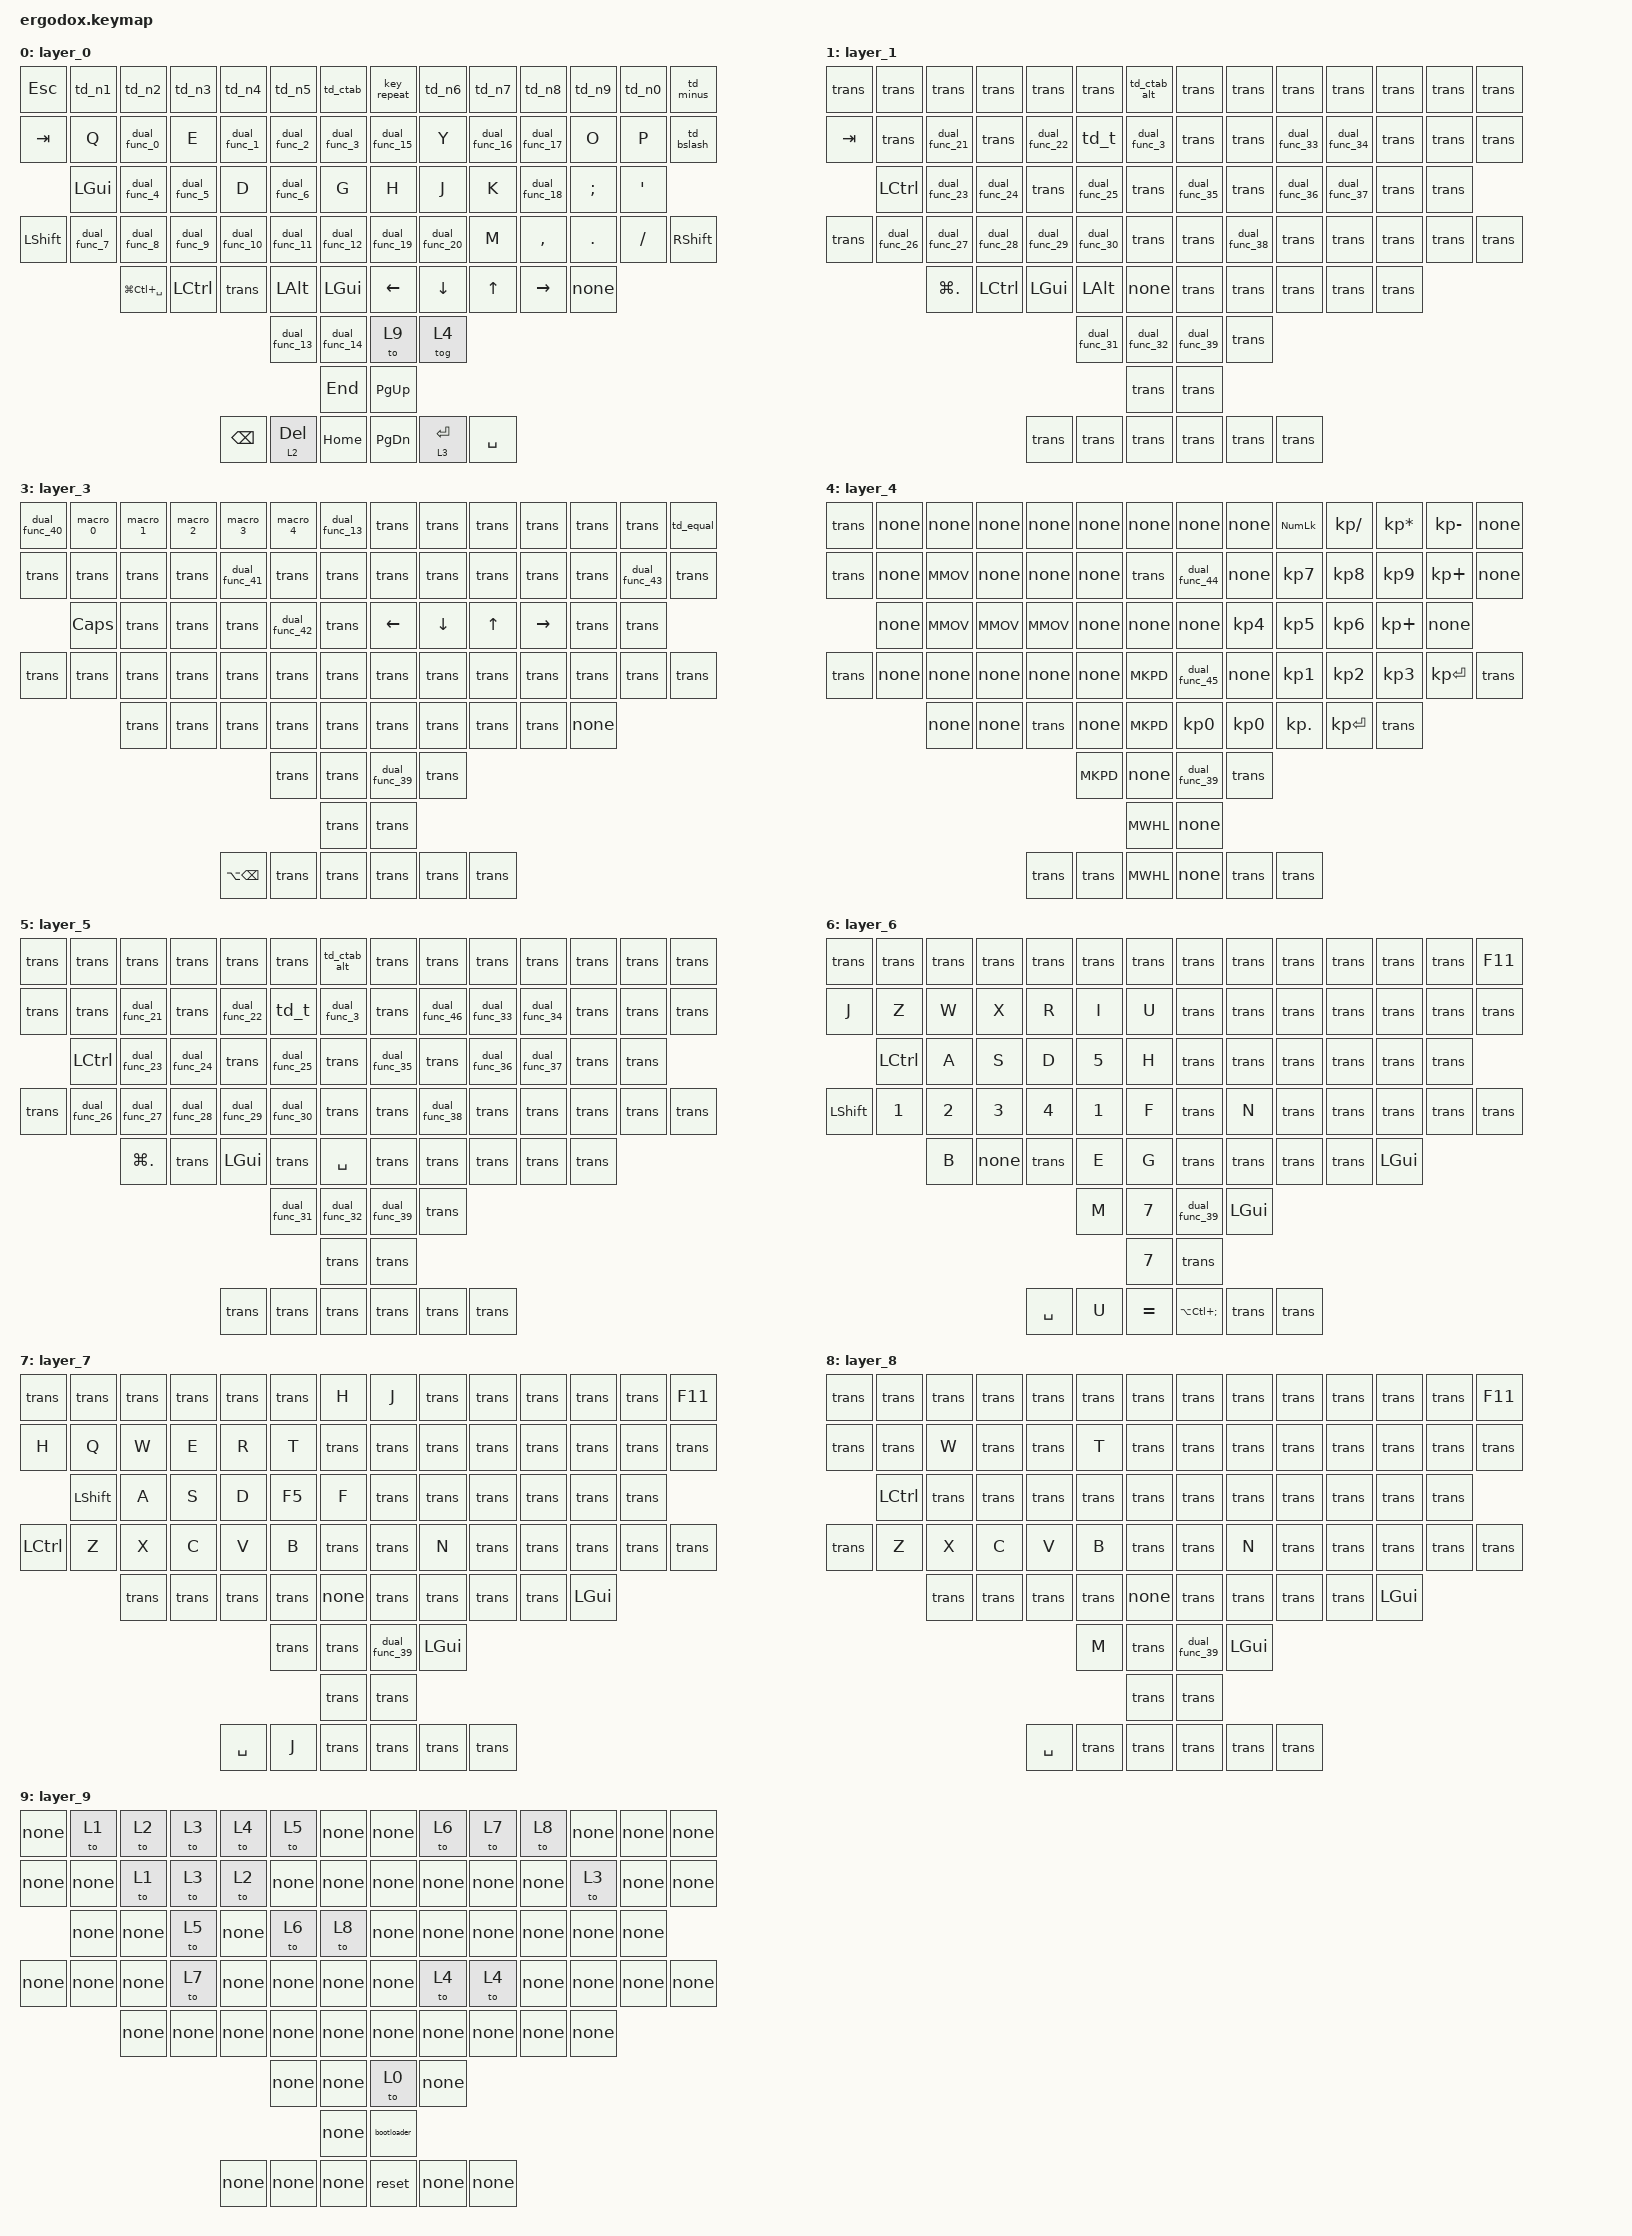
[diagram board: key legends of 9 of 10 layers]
// Auto-generated by qmk_to_zmk.py - Complete keymap conversion
#include <dt-bindings/zmk/keys.h>

/ {
    behaviors {
        // Tri-function number row (tap=number, hold=symbol via mod-tap first binding, double-tap=Fx second binding)
        td_n1: td_n1 { compatible = "zmk,behavior-tap-dance"; #binding-cells = <0>; tapping-term-ms = <300>; bindings = <&mt EXCL N1>, <&kp F1>; };
        td_n2: td_n2 { compatible = "zmk,behavior-tap-dance"; #binding-cells = <0>; tapping-term-ms = <300>; bindings = <&mt AT N2>, <&kp F2>; };
        td_n3: td_n3 { compatible = "zmk,behavior-tap-dance"; #binding-cells = <0>; tapping-term-ms = <300>; bindings = <&mt HASH N3>, <&kp F3>; };
        td_n4: td_n4 { compatible = "zmk,behavior-tap-dance"; #binding-cells = <0>; tapping-term-ms = <300>; bindings = <&mt DLLR N4>, <&kp F4>; };
        td_n5: td_n5 { compatible = "zmk,behavior-tap-dance"; #binding-cells = <0>; tapping-term-ms = <300>; bindings = <&mt PRCNT N5>, <&kp F5>; };
        td_ctab: td_ctab { compatible = "zmk,behavior-tap-dance"; #binding-cells = <0>; tapping-term-ms = <300>; bindings = <&mt LG(LS(A)) LC(TAB)>, <&kp LG(LEFT)>; };
        td_n6: td_n6 { compatible = "zmk,behavior-tap-dance"; #binding-cells = <0>; tapping-term-ms = <300>; bindings = <&mt CARET N6>, <&kp F6>; };
        td_n7: td_n7 { compatible = "zmk,behavior-tap-dance"; #binding-cells = <0>; tapping-term-ms = <300>; bindings = <&mt AMPS N7>, <&kp F7>; };
        td_n8: td_n8 { compatible = "zmk,behavior-tap-dance"; #binding-cells = <0>; tapping-term-ms = <300>; bindings = <&mt ASTRK N8>, <&kp F8>; };
        td_n9: td_n9 { compatible = "zmk,behavior-tap-dance"; #binding-cells = <0>; tapping-term-ms = <300>; bindings = <&mt LPAR N9>, <&kp F9>; };
        td_n0: td_n0 { compatible = "zmk,behavior-tap-dance"; #binding-cells = <0>; tapping-term-ms = <300>; bindings = <&mt RPAR N0>, <&kp F10>; };
        td_minus: td_minus { compatible = "zmk,behavior-tap-dance"; #binding-cells = <0>; tapping-term-ms = <250>; bindings = <&mt UNDER MINUS>, <&kp F11>; };
        td_bslash: td_bslash { compatible = "zmk,behavior-tap-dance"; #binding-cells = <0>; tapping-term-ms = <250>; bindings = <&kp BSLH>, <&kp F12>; };
        td_equal: td_equal { compatible = "zmk,behavior-tap-dance"; #binding-cells = <0>; tapping-term-ms = <250>; bindings = <&mt PLUS EQUAL>, <&kp F12>; };

        // Reused tap dances (workspace, T chord, desktop nav variants)
        td_ctab_alt: td_ctab_alt { compatible = "zmk,behavior-tap-dance"; #binding-cells = <0>; tapping-term-ms = <300>; bindings = <&mt LC(LS(A)) LC(TAB)>, <&kp LA(LEFT)>; };
        td_t: td_t { compatible = "zmk,behavior-tap-dance"; #binding-cells = <0>; tapping-term-ms = <300>; bindings = <&mt LC(T) T>, <&kp LC(LS(T))>; };
        td_t_alt: td_t_alt { compatible = "zmk,behavior-tap-dance"; #binding-cells = <0>; tapping-term-ms = <300>; bindings = <&mt LC(T) T>, <&kp LC(LS(T))>; };
        td_desktop_left: td_desktop_left { compatible = "zmk,behavior-tap-dance"; #binding-cells = <0>; tapping-term-ms = <300>; bindings = <&kp LA(LC(LG(LS(LEFT))))>, <&kp LA(LC(LG(LEFT)))>; };
        td_desktop_right: td_desktop_right { compatible = "zmk,behavior-tap-dance"; #binding-cells = <0>; tapping-term-ms = <300>; bindings = <&kp LA(LC(LG(LS(RIGHT))))>, <&kp LA(LC(LG(RIGHT)))>; };
        td_desktop_left_alt: td_desktop_left_alt { compatible = "zmk,behavior-tap-dance"; #binding-cells = <0>; tapping-term-ms = <300>; bindings = <&kp LA(LC(LG(LS(LEFT))))>, <&kp LA(LC(LG(LEFT)))>; };
        td_desktop_right_alt: td_desktop_right_alt { compatible = "zmk,behavior-tap-dance"; #binding-cells = <0>; tapping-term-ms = <300>; bindings = <&kp LA(LC(LG(LS(RIGHT))))>, <&kp LA(LC(LG(RIGHT)))>; };

        // Dual-function hold-tap keys
        dual_func_0: dual_func_0 { compatible = "zmk,behavior-hold-tap"; #binding-cells = <2>; flavor = "tap-preferred"; tapping-term-ms = <350>; bindings = <&kp LG(W)>, <&kp W>; };
        dual_func_1: dual_func_1 { compatible = "zmk,behavior-hold-tap"; #binding-cells = <2>; flavor = "tap-preferred"; tapping-term-ms = <300>; bindings = <&kp LG(R)>, <&kp R>; };
        dual_func_2: dual_func_2 { compatible = "zmk,behavior-hold-tap"; #binding-cells = <2>; flavor = "tap-preferred"; tapping-term-ms = <350>; bindings = <&kp LG(T)>, <&kp T>; };
        dual_func_3: dual_func_3 { compatible = "zmk,behavior-hold-tap"; #binding-cells = <2>; flavor = "tap-preferred"; tapping-term-ms = <300>; bindings = <&kp TILDE>, <&kp GRAVE>; };
        dual_func_4: dual_func_4 { compatible = "zmk,behavior-hold-tap"; #binding-cells = <2>; flavor = "tap-preferred"; tapping-term-ms = <300>; bindings = <&kp LG(A)>, <&kp A>; };
        dual_func_5: dual_func_5 { compatible = "zmk,behavior-hold-tap"; #binding-cells = <2>; flavor = "tap-preferred"; tapping-term-ms = <300>; bindings = <&kp LG(S)>, <&kp S>; };
        dual_func_6: dual_func_6 { compatible = "zmk,behavior-hold-tap"; #binding-cells = <2>; flavor = "tap-preferred"; tapping-term-ms = <300>; bindings = <&kp LG(F)>, <&kp F>; };
        dual_func_7: dual_func_7 { compatible = "zmk,behavior-hold-tap"; #binding-cells = <2>; flavor = "tap-preferred"; tapping-term-ms = <300>; bindings = <&kp LG(Z)>, <&kp Z>; };
        dual_func_8: dual_func_8 { compatible = "zmk,behavior-hold-tap"; #binding-cells = <2>; flavor = "tap-preferred"; tapping-term-ms = <300>; bindings = <&kp LG(X)>, <&kp X>; };
        dual_func_9: dual_func_9 { compatible = "zmk,behavior-hold-tap"; #binding-cells = <2>; flavor = "tap-preferred"; tapping-term-ms = <300>; bindings = <&kp LG(C)>, <&kp C>; };
        dual_func_10: dual_func_10 { compatible = "zmk,behavior-hold-tap"; #binding-cells = <2>; flavor = "tap-preferred"; tapping-term-ms = <300>; bindings = <&kp LG(V)>, <&kp V>; };
        dual_func_11: dual_func_11 { compatible = "zmk,behavior-hold-tap"; #binding-cells = <2>; flavor = "tap-preferred"; tapping-term-ms = <300>; bindings = <&kp LG(B)>, <&kp B>; };
        dual_func_12: dual_func_12 { compatible = "zmk,behavior-hold-tap"; #binding-cells = <2>; flavor = "tap-preferred"; tapping-term-ms = <300>; bindings = <&kp LPAR>, <&kp LBKT>; };
        dual_func_13: dual_func_13 { compatible = "zmk,behavior-hold-tap"; #binding-cells = <2>; flavor = "tap-preferred"; tapping-term-ms = <300>; bindings = <&kp LG(LS(N2))>, <&kp LG(LS(N1))>; };
        dual_func_14: dual_func_14 { compatible = "zmk,behavior-hold-tap"; #binding-cells = <2>; flavor = "tap-preferred"; tapping-term-ms = <300>; bindings = <&kp LG(LC(Q))>, <&kp C_PLAY_PAUSE>; };
        dual_func_15: dual_func_15 { compatible = "zmk,behavior-hold-tap"; #binding-cells = <2>; flavor = "tap-preferred"; tapping-term-ms = <200>; bindings = <&kp PLUS>, <&kp EQUAL>; };
        dual_func_16: dual_func_16 { compatible = "zmk,behavior-hold-tap"; #binding-cells = <2>; flavor = "tap-preferred"; tapping-term-ms = <300>; bindings = <&kp LG(U)>, <&kp U>; };
        dual_func_17: dual_func_17 { compatible = "zmk,behavior-hold-tap"; #binding-cells = <2>; flavor = "tap-preferred"; tapping-term-ms = <300>; bindings = <&kp LG(I)>, <&kp I>; };
        dual_func_18: dual_func_18 { compatible = "zmk,behavior-hold-tap"; #binding-cells = <2>; flavor = "tap-preferred"; tapping-term-ms = <300>; bindings = <&kp LG(L)>, <&kp L>; };
        dual_func_19: dual_func_19 { compatible = "zmk,behavior-hold-tap"; #binding-cells = <2>; flavor = "tap-preferred"; tapping-term-ms = <300>; bindings = <&kp RPAR>, <&kp RBKT>; };
        dual_func_20: dual_func_20 { compatible = "zmk,behavior-hold-tap"; #binding-cells = <2>; flavor = "tap-preferred"; tapping-term-ms = <350>; bindings = <&kp LG(N)>, <&kp N>; };
        dual_func_21: dual_func_21 { compatible = "zmk,behavior-hold-tap"; #binding-cells = <2>; flavor = "tap-preferred"; tapping-term-ms = <300>; bindings = <&kp LC(W)>, <&kp W>; };
        dual_func_22: dual_func_22 { compatible = "zmk,behavior-hold-tap"; #binding-cells = <2>; flavor = "tap-preferred"; tapping-term-ms = <300>; bindings = <&kp LC(R)>, <&kp R>; };
        dual_func_23: dual_func_23 { compatible = "zmk,behavior-hold-tap"; #binding-cells = <2>; flavor = "tap-preferred"; tapping-term-ms = <300>; bindings = <&kp LC(A)>, <&kp A>; };
        dual_func_24: dual_func_24 { compatible = "zmk,behavior-hold-tap"; #binding-cells = <2>; flavor = "tap-preferred"; tapping-term-ms = <300>; bindings = <&kp LC(S)>, <&kp S>; };
        dual_func_25: dual_func_25 { compatible = "zmk,behavior-hold-tap"; #binding-cells = <2>; flavor = "tap-preferred"; tapping-term-ms = <300>; bindings = <&kp LC(F)>, <&kp F>; };
        dual_func_26: dual_func_26 { compatible = "zmk,behavior-hold-tap"; #binding-cells = <2>; flavor = "tap-preferred"; tapping-term-ms = <300>; bindings = <&kp LC(Z)>, <&kp Z>; };
        dual_func_27: dual_func_27 { compatible = "zmk,behavior-hold-tap"; #binding-cells = <2>; flavor = "tap-preferred"; tapping-term-ms = <300>; bindings = <&kp LC(X)>, <&kp X>; };
        dual_func_28: dual_func_28 { compatible = "zmk,behavior-hold-tap"; #binding-cells = <2>; flavor = "tap-preferred"; tapping-term-ms = <300>; bindings = <&kp LC(C)>, <&kp C>; };
        dual_func_29: dual_func_29 { compatible = "zmk,behavior-hold-tap"; #binding-cells = <2>; flavor = "tap-preferred"; tapping-term-ms = <300>; bindings = <&kp LC(V)>, <&kp V>; };
        dual_func_30: dual_func_30 { compatible = "zmk,behavior-hold-tap"; #binding-cells = <2>; flavor = "tap-preferred"; tapping-term-ms = <300>; bindings = <&kp LC(B)>, <&kp B>; };
        dual_func_31: dual_func_31 { compatible = "zmk,behavior-hold-tap"; #binding-cells = <2>; flavor = "tap-preferred"; tapping-term-ms = <300>; bindings = <&kp LA(PSCR)>, <&kp LG(LS(S))>; };
        dual_func_32: dual_func_32 { compatible = "zmk,behavior-hold-tap"; #binding-cells = <2>; flavor = "tap-preferred"; tapping-term-ms = <300>; bindings = <&kp LG(L)>, <&kp C_PLAY_PAUSE>; };
        dual_func_33: dual_func_33 { compatible = "zmk,behavior-hold-tap"; #binding-cells = <2>; flavor = "tap-preferred"; tapping-term-ms = <300>; bindings = <&kp LC(U)>, <&kp U>; };
        dual_func_34: dual_func_34 { compatible = "zmk,behavior-hold-tap"; #binding-cells = <2>; flavor = "tap-preferred"; tapping-term-ms = <300>; bindings = <&kp LC(I)>, <&kp I>; };
        dual_func_35: dual_func_35 { compatible = "zmk,behavior-hold-tap"; #binding-cells = <2>; flavor = "tap-preferred"; tapping-term-ms = <300>; bindings = <&kp LG(LC(LEFT))>, <&kp H>; };
        dual_func_36: dual_func_36 { compatible = "zmk,behavior-hold-tap"; #binding-cells = <2>; flavor = "tap-preferred"; tapping-term-ms = <300>; bindings = <&kp LG(TAB)>, <&kp K>; };
        dual_func_37: dual_func_37 { compatible = "zmk,behavior-hold-tap"; #binding-cells = <2>; flavor = "tap-preferred"; tapping-term-ms = <300>; bindings = <&kp LG(LC(RIGHT))>, <&kp L>; };
        dual_func_38: dual_func_38 { compatible = "zmk,behavior-hold-tap"; #binding-cells = <2>; flavor = "tap-preferred"; tapping-term-ms = <300>; bindings = <&kp LC(N)>, <&kp N>; };
        dual_func_39: dual_func_39 { compatible = "zmk,behavior-hold-tap"; #binding-cells = <2>; flavor = "balanced"; tapping-term-ms = <200>; bindings = <&to 0>, <&to 9>; };
        dual_func_40: dual_func_40 { compatible = "zmk,behavior-hold-tap"; #binding-cells = <2>; flavor = "tap-preferred"; tapping-term-ms = <300>; bindings = <&kp LC(GRAVE)>, <&kp GRAVE>; };
        dual_func_41: dual_func_41 { compatible = "zmk,behavior-hold-tap"; #binding-cells = <2>; flavor = "balanced"; tapping-term-ms = <300>; bindings = <&kp LG(LS(H))>, <&kp LA(LG(F))>; };
        dual_func_42: dual_func_42 { compatible = "zmk,behavior-hold-tap"; #binding-cells = <2>; flavor = "balanced"; tapping-term-ms = <300>; bindings = <&kp LG(LS(F))>, <&kp LG(F)>; };
        dual_func_43: dual_func_43 { compatible = "zmk,behavior-hold-tap"; #binding-cells = <2>; flavor = "balanced"; tapping-term-ms = <300>; bindings = <&kp LG(LS(P))>, <&kp LG(P)>; };
        dual_func_44: dual_func_44 { compatible = "zmk,behavior-hold-tap"; #binding-cells = <2>; flavor = "balanced"; tapping-term-ms = <300>; bindings = <&kp BR_UP>, <&kp VOL_UP>; };
        dual_func_45: dual_func_45 { compatible = "zmk,behavior-hold-tap"; #binding-cells = <2>; flavor = "balanced"; tapping-term-ms = <300>; bindings = <&kp BR_DOWN>, <&kp VOL_DOWN>; };
        dual_func_46: dual_func_46 { compatible = "zmk,behavior-hold-tap"; #binding-cells = <2>; flavor = "tap-preferred"; tapping-term-ms = <300>; bindings = <&kp LC(Y)>, <&kp Y>; };

        // Macros replicating ST_MACRO_0..4 (Hash repeated n times + space)
        macro_0: macro_0 { compatible = "zmk,behavior-macro"; #binding-cells = <0>; bindings = <&kp HASH>, <&kp SPACE>; };
        macro_1: macro_1 { compatible = "zmk,behavior-macro"; #binding-cells = <0>; bindings = <&kp HASH>, <&kp HASH>, <&kp SPACE>; };
        macro_2: macro_2 { compatible = "zmk,behavior-macro"; #binding-cells = <0>; bindings = <&kp HASH>, <&kp HASH>, <&kp HASH>, <&kp SPACE>; };
        macro_3: macro_3 { compatible = "zmk,behavior-macro"; #binding-cells = <0>; bindings = <&kp HASH>, <&kp HASH>, <&kp HASH>, <&kp HASH>, <&kp SPACE>; };
        macro_4: macro_4 { compatible = "zmk,behavior-macro"; #binding-cells = <0>; bindings = <&kp HASH>, <&kp HASH>, <&kp HASH>, <&kp HASH>, <&kp HASH>, <&kp SPACE>; };
    };
};


/ {
    keymap {
        compatible = "zmk,keymap";

        layer_0 {
            bindings = <
                &kp ESC &td_n1 &td_n2 &td_n3 &td_n4 &td_n5 &td_ctab &key_repeat &td_n6 &td_n7 &td_n8 &td_n9 &td_n0 &td_minus
                &kp TAB &kp Q &dual_func_0 &kp E &dual_func_1 &dual_func_2 &dual_func_3 &dual_func_15 &kp Y &dual_func_16 &dual_func_17 &kp O &kp P &td_bslash
                &kp LGUI &dual_func_4 &dual_func_5 &kp D &dual_func_6 &kp G                                       &kp H &kp J &kp K &dual_func_18 &kp SEMI &kp SQT
                &kp LSHFT &dual_func_7 &dual_func_8 &dual_func_9 &dual_func_10 &dual_func_11 &dual_func_12         &dual_func_19 &dual_func_20 &kp M &kp COMMA &kp DOT &kp FSLH &kp RSHFT
                &kp LG(LC(SPACE)) &kp LCTRL &kp trans &kp LALT &kp LGUI                                         &kp LEFT &kp DOWN &kp UP &kp RIGHT &kp none
                                                &dual_func_13 &dual_func_14 &to 9 &tog 4
                                                           &kp END &kp PG_UP
                                &kp BSPC &lt 2 DEL &kp HOME &kp PG_DN &lt 3 RET &kp SPACE
            >;
        };

        layer_1 {
            bindings = <
                &kp trans &kp trans &kp trans &kp trans &kp trans &kp trans &td_ctab_alt &kp trans &kp trans &kp trans &kp trans &kp trans &kp trans &kp trans &kp TAB &kp trans &dual_func_21 &kp trans &dual_func_22 &td_t &dual_func_3 &kp trans &kp trans &dual_func_33 &dual_func_34 &kp trans &kp trans &kp trans &kp LCTRL &dual_func_23 &dual_func_24 &kp trans &dual_func_25 &kp trans &dual_func_35 &kp trans &dual_func_36 &dual_func_37 &kp trans &kp trans &kp trans &dual_func_26 &dual_func_27 &dual_func_28 &dual_func_29 &dual_func_30 &kp trans &kp trans &dual_func_38 &kp trans &kp trans &kp trans &kp trans &kp trans &kp LG(DOT) &kp LCTRL &kp LGUI &kp LALT &kp none &kp trans &kp trans &kp trans &kp trans &kp trans &dual_func_31 &dual_func_32 &dual_func_39 &kp trans &kp trans &kp trans &kp trans &kp trans &kp trans &kp trans &kp trans &kp trans
            >;
        };

        layer_2 {
            bindings = <
                &kp none &kp LA(LC(LS(N1))) &kp LA(LC(LS(N2))) &kp LA(LC(LS(N3))) &kp LA(LC(LS(N4))) &kp none &kp none &kp none &kp none &kp none &kp none &kp none &kp LA(LC(MINUS)) &kp LA(LC(EQUAL)) &kp none &kp none &kp LA(LC(RET)) &kp none &kp LC(LSHFT) &kp MEH &kp LG(GRAVE) &kp none &kp none &kp none &kp none &kp none &kp none &kp none &kp none &td_desktop_left &kp LA(LSHFT) &td_desktop_right &kp LG(LC(F)) &kp none &kp LC(LEFT) &kp none &kp LC(UP) &kp LC(RIGHT) &kp none &kp none &kp none &kp none &kp none &kp LA(LC(C)) &kp none &kp none &kp none &kp none &kp none &kp none &kp none &kp none &kp none &kp none &kp none &kp none &kp none &kp none &kp none &td_desktop_left_alt &kp none &kp LA(LC(RET)) &td_desktop_right_alt &kp none &kp none &kp none &dual_func_39 &kp trans &kp none &kp LA(LC(EQUAL)) &kp none &kp trans &kp none &kp LA(LC(MINUS)) &kp LA(LC(RET)) &kp none
            >;
        };

        layer_3 {
            bindings = <
                &dual_func_40 &macro_0 &macro_1 &macro_2 &macro_3 &macro_4 &dual_func_13 &kp trans &kp trans &kp trans &kp trans &kp trans &kp trans &td_equal &kp trans &kp trans &kp trans &kp trans &dual_func_41 &kp trans &kp trans &kp trans &kp trans &kp trans &kp trans &kp trans &dual_func_43 &kp trans &kp CAPS &kp trans &kp trans &kp trans &dual_func_42 &kp trans &kp LEFT &kp DOWN &kp UP &kp RIGHT &kp trans &kp trans &kp trans &kp trans &kp trans &kp trans &kp trans &kp trans &kp trans &kp trans &kp trans &kp trans &kp trans &kp trans &kp trans &kp trans &kp trans &kp trans &kp trans &kp trans &kp trans &kp trans &kp trans &kp trans &kp trans &kp none &kp trans &kp trans &dual_func_39 &kp trans &kp trans &kp trans &kp LA(BSPC) &kp trans &kp trans &kp trans &kp trans &kp trans
            >;
        };

        layer_4 {
            bindings = <
                &kp trans &kp none &kp none &kp none &kp none &kp none &kp none &kp none &kp none &kp KP_NUM &kp KP_DIVIDE &kp KP_MULTIPLY &kp KP_MINUS &kp none &kp trans &kp none &kp MMOV &kp none &kp none &kp none &kp trans &dual_func_44 &kp none &kp KP_N7 &kp KP_N8 &kp KP_N9 &kp KP_PLUS &kp none &kp none &kp MMOV &kp MMOV &kp MMOV &kp none &kp none &kp none &kp KP_N4 &kp KP_N5 &kp KP_N6 &kp KP_PLUS &kp none &kp trans &kp none &kp none &kp none &kp none &kp none &kp MKPD &dual_func_45 &kp none &kp KP_N1 &kp KP_N2 &kp KP_N3 &kp KP_ENTER &kp trans &kp none &kp none &kp trans &kp none &kp MKPD &kp KP_N0 &kp KP_N0 &kp KP_DOT &kp KP_ENTER &kp trans &kp MKPD &kp none &dual_func_39 &kp trans &kp MWHL &kp none &kp trans &kp trans &kp MWHL &kp none &kp trans &kp trans
            >;
        };

        layer_5 {
            bindings = <
                &kp trans &kp trans &kp trans &kp trans &kp trans &kp trans &td_ctab_alt &kp trans &kp trans &kp trans &kp trans &kp trans &kp trans &kp trans &kp trans &kp trans &dual_func_21 &kp trans &dual_func_22 &td_t &dual_func_3 &kp trans &dual_func_46 &dual_func_33 &dual_func_34 &kp trans &kp trans &kp trans &kp LCTRL &dual_func_23 &dual_func_24 &kp trans &dual_func_25 &kp trans &dual_func_35 &kp trans &dual_func_36 &dual_func_37 &kp trans &kp trans &kp trans &dual_func_26 &dual_func_27 &dual_func_28 &dual_func_29 &dual_func_30 &kp trans &kp trans &dual_func_38 &kp trans &kp trans &kp trans &kp trans &kp trans &kp LG(DOT) &kp trans &kp LGUI &kp trans &kp SPACE &kp trans &kp trans &kp trans &kp trans &kp trans &dual_func_31 &dual_func_32 &dual_func_39 &kp trans &kp trans &kp trans &kp trans &kp trans &kp trans &kp trans &kp trans &kp trans
            >;
        };

        layer_6 {
            bindings = <
                &kp trans &kp trans &kp trans &kp trans &kp trans &kp trans &kp trans &kp trans &kp trans &kp trans &kp trans &kp trans &kp trans &kp F11 &kp J &kp Z &kp W &kp X &kp R &kp I &kp U &kp trans &kp trans &kp trans &kp trans &kp trans &kp trans &kp trans &kp LCTRL &kp A &kp S &kp D &kp N5 &kp H &kp trans &kp trans &kp trans &kp trans &kp trans &kp trans &kp LSHFT &kp N1 &kp N2 &kp N3 &kp N4 &kp N1 &kp F &kp trans &kp N &kp trans &kp trans &kp trans &kp trans &kp trans &kp B &kp none &kp trans &kp E &kp G &kp trans &kp trans &kp trans &kp trans &kp LGUI &kp M &kp N7 &dual_func_39 &kp LGUI &kp N7 &kp trans &kp SPACE &kp U &kp EQUAL &kp LA(LC(SEMI)) &kp trans &kp trans
            >;
        };

        layer_7 {
            bindings = <
                &kp trans &kp trans &kp trans &kp trans &kp trans &kp trans &kp H &kp J &kp trans &kp trans &kp trans &kp trans &kp trans &kp F11 &kp H &kp Q &kp W &kp E &kp R &kp T &kp trans &kp trans &kp trans &kp trans &kp trans &kp trans &kp trans &kp trans &kp LSHFT &kp A &kp S &kp D &kp F5 &kp F &kp trans &kp trans &kp trans &kp trans &kp trans &kp trans &kp LCTRL &kp Z &kp X &kp C &kp V &kp B &kp trans &kp trans &kp N &kp trans &kp trans &kp trans &kp trans &kp trans &kp trans &kp trans &kp trans &kp trans &kp none &kp trans &kp trans &kp trans &kp trans &kp LGUI &kp trans &kp trans &dual_func_39 &kp LGUI &kp trans &kp trans &kp SPACE &kp J &kp trans &kp trans &kp trans &kp trans
            >;
        };

        layer_8 {
            bindings = <
                &kp trans &kp trans &kp trans &kp trans &kp trans &kp trans &kp trans &kp trans &kp trans &kp trans &kp trans &kp trans &kp trans &kp F11 &kp trans &kp trans &kp W &kp trans &kp trans &kp T &kp trans &kp trans &kp trans &kp trans &kp trans &kp trans &kp trans &kp trans &kp LCTRL &kp trans &kp trans &kp trans &kp trans &kp trans &kp trans &kp trans &kp trans &kp trans &kp trans &kp trans &kp trans &kp Z &kp X &kp C &kp V &kp B &kp trans &kp trans &kp N &kp trans &kp trans &kp trans &kp trans &kp trans &kp trans &kp trans &kp trans &kp trans &kp none &kp trans &kp trans &kp trans &kp trans &kp LGUI &kp M &kp trans &dual_func_39 &kp LGUI &kp trans &kp trans &kp SPACE &kp trans &kp trans &kp trans &kp trans &kp trans
            >;
        };

        layer_9 {
            bindings = <
                &kp none &to 1 &to 2 &to 3 &to 4 &to 5 &kp none &kp none &to 6 &to 7 &to 8 &kp none &kp none &kp none &kp none &kp none &to 1 &to 3 &to 2 &kp none &kp none &kp none &kp none &kp none &kp none &to 3 &kp none &kp none &kp none &kp none &to 5 &kp none &to 6 &to 8 &kp none &kp none &kp none &kp none &kp none &kp none &kp none &kp none &kp none &to 7 &kp none &kp none &kp none &kp none &to 4 &to 4 &kp none &kp none &kp none &kp none &kp none &kp none &kp none &kp none &kp none &kp none &kp none &kp none &kp none &kp none &kp none &kp none &to 0 &kp none &kp none &kp bootloader &kp none &kp none &kp none &kp reset &kp none &kp none
            >;
        };

    };
};
